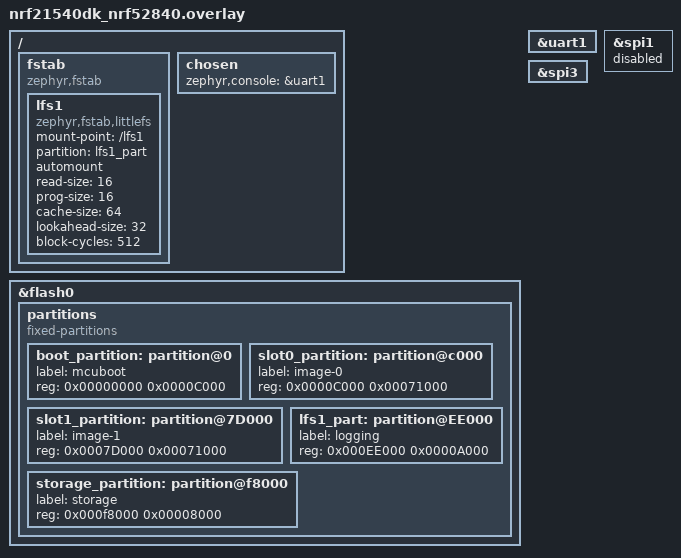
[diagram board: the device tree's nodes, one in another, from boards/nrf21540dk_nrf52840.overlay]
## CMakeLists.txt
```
# SPDX-License-Identifier: Apache-2.0

cmake_minimum_required(VERSION 3.20.0)

find_package(Zephyr REQUIRED HINTS $ENV{ZEPHYR_BASE})
project(link_control_peripheral)

target_sources(app PRIVATE 
	src/peripheral.c
	${CMAKE_CURRENT_SOURCE_DIR}/../common/src/link_control/link_control.c
	${CMAKE_CURRENT_SOURCE_DIR}/../common/src/link_control/link_control_service.c
	${CMAKE_CURRENT_SOURCE_DIR}/../common/src/conn_adv_pair/conn_adv_pair.c
)

target_include_directories(app PRIVATE
	${CMAKE_CURRENT_SOURCE_DIR}/../common/include
)
```

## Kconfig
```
config LCS_RSSI_INTERVAL_MS
	int "RSSI measurement interval in milliseconds"
	default 1000
	help
	  Defines the interval between RSSI measurements in milliseconds.

config LCS_PERIPHERAL_STACK_SIZE
	int "Stack size for LCS Peripheral thread"
	default 1024

config LCS_PERIPHERAL_THREAD_PRIORITY
	int "Priority for LCS Peripheral thread"
	default 7

source "Kconfig.zephyr"
```

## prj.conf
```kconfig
# Enable console
CONFIG_CONSOLE=y

# Enable shell
CONFIG_SHELL=y
CONFIG_SHELL_STACK_SIZE=4096

# Adjust system memory
CONFIG_MAIN_STACK_SIZE=2048
CONFIG_HEAP_MEM_POOL_SIZE=2048
CONFIG_SYSTEM_WORKQUEUE_STACK_SIZE=2048

# Enable BLE
CONFIG_BT=y
CONFIG_BT_DEVICE_NAME="LCS Peripheral"
CONFIG_BT_CTLR_ADV_EXT=y
CONFIG_BT_EXT_ADV=y
CONFIG_BT_PHY_UPDATE=y
CONFIG_BT_CTLR_CONN_RSSI=y
CONFIG_BT_CTLR_TX_PWR_DYNAMIC_CONTROL=y
CONFIG_BT_MAX_CONN=2
CONFIG_BT_GATT_CLIENT=y
CONFIG_BT_GATT_DM=y
CONFIG_BT_PERIPHERAL=y
CONFIG_BT_HCI_TX_STACK_SIZE=8192
CONFIG_BT_ATT_TX_COUNT=4
CONFIG_BT_BUF_CMD_TX_COUNT=16
CONFIG_BT_CTLR_SDC_TX_PACKET_COUNT=16
CONFIG_BT_BUF_ACL_TX_COUNT=200
CONFIG_BT_L2CAP_TX_MTU=247
CONFIG_BT_USER_DATA_LEN_UPDATE=y
CONFIG_BT_BUF_ACL_RX_SIZE=251
CONFIG_BT_BUF_ACL_TX_SIZE=251
CONFIG_BT_CTLR_DATA_LENGTH_MAX=251
CONFIG_BT_LOG_LEVEL_INF=y

# Enable bonding
CONFIG_BT_MAX_PAIRED=1
CONFIG_BT_SETTINGS=y

CONFIG_NVS=y
CONFIG_SETTINGS=y

# Config logger
CONFIG_LOG=y
CONFIG_LOG_BUFFER_SIZE=8192
CONFIG_LOG_PROCESS_THREAD_STACK_SIZE=4096
```

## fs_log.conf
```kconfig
CONFIG_SHELL_LOG_BACKEND=n
CONFIG_LOG_BACKEND_UART=n
CONFIG_LOG_BACKEND_RTT=n
```

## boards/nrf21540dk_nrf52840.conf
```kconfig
CONFIG_MPSL=y
CONFIG_MPSL_FEM=y
CONFIG_MPSL_FEM_NRF21540_GPIO_SPI=y

# Log backend config
CONFIG_LOG_BACKEND_FS_FILE_SIZE=1024
CONFIG_LOG_BACKEND_FS_FILES_LIMIT=40
```

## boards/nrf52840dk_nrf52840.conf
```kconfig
#
# Copyright (c) 2021 Nordic Semiconductor ASA
#
# SPDX-License-Identifier: Apache-2.0
#

CONFIG_NORDIC_QSPI_NOR=y
CONFIG_NORDIC_QSPI_NOR_FLASH_LAYOUT_PAGE_SIZE=4096

# Log backend config
#CONFIG_LOG_BACKEND_FS_FILE_SIZE=4096
#CONFIG_LOG_BACKEND_FS_FILES_LIMIT=256
```

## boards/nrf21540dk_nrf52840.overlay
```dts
/ {
	fstab {
		compatible = "zephyr,fstab";
		lfs1: lfs1 {
			compatible = "zephyr,fstab,littlefs";
			mount-point = "/lfs1";
			partition = <&lfs1_part>;
			automount;
			read-size = <16>;
			prog-size = <16>;
			cache-size = <64>;
			lookahead-size = <32>;
			block-cycles = <512>;
		};
	};
	
	chosen {
		zephyr,console = &uart1;
	};
};

/delete-node/ &slot0_partition;
/delete-node/ &slot1_partition;
/delete-node/ &storage_partition;

&flash0 {
	partitions {
		compatible = "fixed-partitions";
		#address-cells = <1>;
		#size-cells = <1>;

		boot_partition: partition@0 {
			label = "mcuboot";
			reg = <0x00000000 0x0000C000>;
		};
		slot0_partition: partition@c000 {
			label = "image-0";
			reg = <0x0000C000 0x00071000>;
		};
		slot1_partition: partition@7D000 {
			label = "image-1";
			reg = <0x0007D000 0x00071000>;
		};

		lfs1_part: partition@EE000 {
			label = "logging";
			reg = <0x000EE000 0x0000A000>;
		};

		storage_partition: partition@f8000 {
			label = "storage";
			reg = <0x000f8000 0x00008000>;
		};
	};
};

&uart1 {
	status = "okay";
};

&spi1 {
	status = "disabled";
};

arduino_spi: &spi3 {};
```

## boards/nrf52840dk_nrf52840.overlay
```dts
/*
 * Copyright (c) 2021 Nordic Semiconductor ASA
 *
 * SPDX-License-Identifier: Apache-2.0
 */

/*
/ {
	fstab {
		compatible = "zephyr,fstab";
		lfs1: lfs1 {
			compatible = "zephyr,fstab,littlefs";
			mount-point = "/lfs1";
			partition = <&lfs1_part>;
			automount;
			read-size = <16>;
			prog-size = <16>;
			cache-size = <64>;
			lookahead-size = <64>;
			block-cycles = <512>;
		};
	};
};

&mx25r64 {
	partitions {
		compatible = "fixed-partitions";
		#address-cells = <1>;
		#size-cells = <1>;

		lfs1_part: partition@0 {
			label = "logging";
			reg = <0x00000000 0x100000>;
		};
	};
};
*/
```

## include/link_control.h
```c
#ifndef LINK_CONTROL_H__
#define LINK_CONTROL_H__

#include <stdint.h>
#include <zephyr/bluetooth/bluetooth.h>

extern int8_t current_tx_power;
extern struct bt_conn *current_conn;

// Set the TX power level for a connection
int set_tx_power(uint8_t handle_type, uint16_t handle, int8_t tx_pwr_lvl);

// Read connection RSSI
int read_conn_rssi(uint16_t handle, int8_t *rssi);

// Change the connection interval
int change_connection_interval(struct bt_conn *conn, uint16_t interval_us);

// Update the connection PHY
int update_phy(struct bt_conn *conn, uint8_t phy);

#endif
```

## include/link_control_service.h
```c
#ifndef LINK_CONTROL_SERVICE_H__
#define LINK_CONTROL_SERVICE_H__

#include <zephyr/types.h>
#include <zephyr/bluetooth/conn.h>
#include <zephyr/bluetooth/uuid.h>
#include <zephyr/bluetooth/gatt.h>

#define BT_UUID_LCS_VAL \
    BT_UUID_128_ENCODE(0x430EBAD0, 0x5C25, 0x469E, 0xA162, 0xA1C9DC50A8FD)
#define BT_UUID_LCS_TX_PWR_VAL \
    BT_UUID_128_ENCODE(0x430EBAD1, 0x5C25, 0x469E, 0xA162, 0xA1C9DC50A8FD)
#define BT_UUID_LCS_RSSI_VAL \
    BT_UUID_128_ENCODE(0x430EBAD2, 0x5C25, 0x469E, 0xA162, 0xA1C9DC50A8FD)
#define BT_UUID_LCS_THROUGHPUT_VAL \
	BT_UUID_128_ENCODE(0x430EBAD3, 0x5C25, 0x469E, 0xA162, 0xA1C9DC50A8FD)
#define BT_UUID_LCS           BT_UUID_DECLARE_128(BT_UUID_LCS_VAL)
#define BT_UUID_LCS_TX_PWR    BT_UUID_DECLARE_128(BT_UUID_LCS_TX_PWR_VAL)
#define BT_UUID_LCS_RSSI      BT_UUID_DECLARE_128(BT_UUID_LCS_RSSI_VAL)
#define BT_UUID_LCS_THROUGHPUT BT_UUID_DECLARE_128(BT_UUID_LCS_THROUGHPUT_VAL)

void update_rssi(struct bt_conn *conn, int16_t new_rssi);

#endif
```

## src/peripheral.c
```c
#include <zephyr/types.h>
#include <zephyr/kernel.h>
#include <zephyr/drivers/uart.h>
#include <zephyr/bluetooth/bluetooth.h>
#include <zephyr/bluetooth/conn.h>
#include <zephyr/bluetooth/uuid.h>
#include <zephyr/bluetooth/gatt.h>
#include <zephyr/bluetooth/hci.h>
#include <zephyr/bluetooth/hci_vs.h>
#include <zephyr/settings/settings.h>
#include <stdio.h>
#include <string.h>
#include <zephyr/logging/log.h>
#include <zephyr/shell/shell.h>
#if defined(CONFIG_FILE_SYSTEM)
#include <zephyr/fs/fs.h>
#endif

#include "link_control.h"
#include "link_control_service.h"

LOG_MODULE_REGISTER(link_control_peripheral);

#define DEVICE_NAME CONFIG_BT_DEVICE_NAME
#define DEVICE_NAME_LEN (sizeof(DEVICE_NAME) - 1)
#define STACKSIZE 1024 
#define PRIORITY 7

int8_t current_tx_power;
static K_SEM_DEFINE(ble_init_ok, 0, 1);
static K_SEM_DEFINE(ble_connected, 0, 1);
struct bt_conn *current_conn;

static const struct bt_data ad[] = {
    BT_DATA_BYTES(BT_DATA_FLAGS, (BT_LE_AD_GENERAL | BT_LE_AD_NO_BREDR)),
    BT_DATA(BT_DATA_NAME_COMPLETE, DEVICE_NAME, DEVICE_NAME_LEN),
};

static const struct bt_data sd[] = {
    BT_DATA_BYTES(BT_DATA_UUID128_ALL, BT_UUID_LCS_VAL),
};

static struct bt_le_ext_adv *adv;

static void start_advertising(void) {
	int err;
	struct bt_le_adv_param adv_param = {
		.id = BT_ID_DEFAULT,
		.sid = 0U,
		.secondary_max_skip = 0U,
		.options = (BT_LE_ADV_OPT_EXT_ADV |
			    BT_LE_ADV_OPT_CONNECTABLE |
			    BT_LE_ADV_OPT_CODED),
		.interval_min = BT_GAP_ADV_FAST_INT_MIN_2,
		.interval_max = BT_GAP_ADV_FAST_INT_MAX_2,
		.peer = NULL,
	};

	LOG_INF("Creating a Coded PHY connectable non-scannable advertising set");
	err = bt_le_ext_adv_create(&adv_param, NULL, &adv);
	if (err) {
		LOG_ERR("Failed to create Coded PHY extended advertising set (err %d)", err);
		return;
	}

	LOG_INF("Setting extended advertising data");
	err = bt_le_ext_adv_set_data(adv, ad, ARRAY_SIZE(ad), NULL, 0);
	if (err) {
		LOG_ERR("Failed to set extended advertising data (err %d)", err);
		return;
	}

	LOG_INF("Starting Extended Advertising (connectable non-scannable)");
	err = bt_le_ext_adv_start(adv, BT_LE_EXT_ADV_START_DEFAULT);
	if (err) {
		LOG_ERR("Failed to start extended advertising set (err %d)", err);
		return;
	}

    set_tx_power(BT_HCI_VS_LL_HANDLE_TYPE_ADV, 0, current_tx_power);
}

static struct bt_gatt_exchange_params exchange_params;

static void exchange_func(struct bt_conn *conn, uint8_t err,
    struct bt_gatt_exchange_params *params)
{
    if (!err) {
        uint32_t bt_max_send_len = bt_gatt_get_mtu(conn) - 3;
        LOG_INF("max send len is %d", bt_max_send_len);
    }
}

static void connected(struct bt_conn *conn, uint8_t err) {
    char addr[BT_ADDR_LE_STR_LEN];

    if (err) {
        LOG_ERR("Connection failed (err %u)", err);
        return;
    }

    bt_addr_le_to_str(bt_conn_get_dst(conn), addr, sizeof(addr));
    LOG_INF("Connected %s", addr);

    err = bt_le_ext_adv_stop(adv);
    if (err) {
        LOG_ERR("Failed to stop advertising, err: %d", err);
    }

    current_conn = bt_conn_ref(conn);
    uint16_t conn_handle;
    bt_hci_get_conn_handle(current_conn, &conn_handle);
    set_tx_power(BT_HCI_VS_LL_HANDLE_TYPE_CONN, conn_handle, current_tx_power);

	exchange_params.func = exchange_func;
	err = bt_gatt_exchange_mtu(current_conn, &exchange_params);
	if (err) {
		LOG_ERR("MTU exchange failed (err %d)", err);
	}
    
    k_sem_give(&ble_connected);
}

static void disconnected(struct bt_conn *conn, uint8_t reason) {
    char addr[BT_ADDR_LE_STR_LEN];
    bt_addr_le_to_str(bt_conn_get_dst(conn), addr, sizeof(addr));
    LOG_INF("Disconnected: %s (reason %u)", addr, reason);

    if (current_conn) {
        bt_conn_unref(current_conn);
        current_conn = NULL;
    }

    start_advertising();
    k_sem_take(&ble_connected, K_MSEC(50));
}

#if IS_ENABLED(CONFIG_BT_USER_PHY_UPDATE)
static void le_phy_updated(struct bt_conn *conn, struct bt_conn_le_phy_info *param) {
    char addr[BT_ADDR_LE_STR_LEN];
    bt_addr_le_to_str(bt_conn_get_dst(conn), addr, sizeof(addr));
    LOG_INF("LE PHY Updated: %s Tx 0x%x, Rx 0x%x", addr, param->tx_phy, param->rx_phy);
}
#endif

BT_CONN_CB_DEFINE(conn_callbacks) = {
    .connected = connected,
    .disconnected = disconnected,
#if IS_ENABLED(CONFIG_BT_USER_PHY_UPDATE)
    .le_phy_updated = le_phy_updated,
#endif
};

int main(void) {
    int err = bt_enable(NULL);
    if (err) {
        LOG_ERR("Bluetooth init failed (err %d)", err);
        return 0;
    }

    LOG_INF("Bluetooth initialized");
    k_sem_give(&ble_init_ok);

    if (IS_ENABLED(CONFIG_SETTINGS)) {
        settings_load();
    }

    start_advertising();
    return 0;
}

void ble_write_thread(void) {
    k_sem_take(&ble_init_ok, K_FOREVER);

    while (true) {
        k_sem_take(&ble_connected, K_FOREVER);
        
        uint16_t conn_handle;
        bt_hci_get_conn_handle(current_conn, &conn_handle);
        
        int8_t rssi;
        int err = read_conn_rssi(conn_handle, &rssi);
        if (err == 0) {
            update_rssi(current_conn, rssi);
			LOG_INF("RSSI: %i", rssi);
        }

        k_sem_give(&ble_connected);
        k_msleep(CONFIG_LCS_RSSI_INTERVAL_MS);
    }
}

K_THREAD_DEFINE(ble_write_thread_id, STACKSIZE, ble_write_thread, NULL, NULL, NULL, PRIORITY, 0, 0);

#if defined(CONFIG_FILE_SYSTEM)
static int cmd_remove_logs(const struct shell *shell, size_t argc, char **argv) {
    int res;
    struct fs_dir_t dirp;
    struct fs_dirent entry;

	char dir_path[64] = "/lfs1";

    fs_dir_t_init(&dirp);

    res = fs_opendir(&dirp, dir_path);
    if (res) {
        shell_error(shell, "Error opening directory %s [%d]\n", dir_path, res);
        return res;
    }

    shell_print(shell, "Clearing directory %s\n", dir_path);
    for (;;) {
        char file_path[PATH_MAX] = { 0 };

        res = fs_readdir(&dirp, &entry);

        /* entry.name[0] == 0 means end-of-dir */
        if (res || entry.name[0] == 0) {
            break;
        }

        /* Delete file or sub directory */
        snprintf(file_path, sizeof(file_path), "%s/%s", dir_path, entry.name);
        res = fs_unlink(file_path);
        if (res) {
            shell_error(shell, "Error deleting file/dir [%d]\n", res);
            fs_closedir(&dirp);
            return res;
        }
    }

    fs_closedir(&dirp);
    shell_print(shell, "Directory %s cleared successfully\n", dir_path);
	return 0;
}


SHELL_STATIC_SUBCMD_SET_CREATE(link_control_cmds,
	SHELL_CMD(remove_logs, NULL, "Removes all logs", cmd_remove_logs),
    SHELL_SUBCMD_SET_END
);

SHELL_CMD_REGISTER(link_control, &link_control_cmds, "Link Control commands", NULL);
#endif
```
